# MCU_TIMER2_CFG register map
Vendor: Texas Instruments
Peripheral module from a debugger description file (folder J7_AHP).
Registers are 32-bit, read-write, reset 0x0 unless marked. A register's access mark holds for its fields unless they carry their own. Offsets are as the file gives them; lines under a group give offsets from that group; [hi:lo] are bit positions; {n}, {i} and the like mark numbered series; 'fields as' and 'values as' point back to an identical list; <NAME> marks a mode.

## MCU_TIMER2_CFG
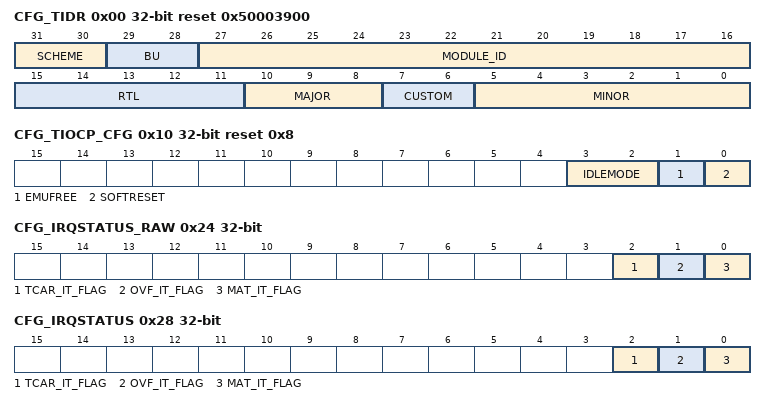
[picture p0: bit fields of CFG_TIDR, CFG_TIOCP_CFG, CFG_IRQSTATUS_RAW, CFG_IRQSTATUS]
0x00 CFG_TIDR ro reset 0x50003900
  [31:30] SCHEME — PID register scheme
  [29:28] BU — Business Unit
  [27:16] MODULE_ID
  [15:11] RTL — RTL revision. Will vary depending on release.
  [10:8] MAJOR — Major revision
  [7:6] CUSTOM
  [5:0] MINOR — Minor revision
0x10 CFG_TIOCP_CFG reset 0x8
  [3:2] IDLEMODE
  [1] EMUFREE — Emulation Mode
  [0] SOFTRESET — Software reset
0x20 CFG_IRQ_EOI
  [0] LINE_NUMBER — Idle Mode
0x24 CFG_IRQSTATUS_RAW access not given
  [2] TCAR_IT_FLAG — Capture Interrupt (access R/W1TS)
  [1] OVF_IT_FLAG — Overflow Interrupt (access R/W1TS)
  [0] MAT_IT_FLAG — Match Interrupt (access R/W1TS)
0x28 CFG_IRQSTATUS access not given
  [2] TCAR_IT_FLAG — Capture Interrupt (access R/W1TC)
  [1] OVF_IT_FLAG — Overflow Interrupt (access R/W1TC)
  [0] MAT_IT_FLAG — Match Interrupt (access R/W1TC)
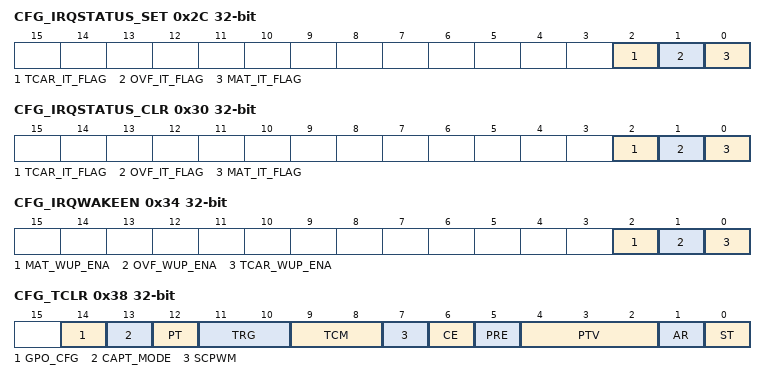
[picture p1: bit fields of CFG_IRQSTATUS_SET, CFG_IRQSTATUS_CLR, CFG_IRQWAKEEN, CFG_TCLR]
0x2C CFG_IRQSTATUS_SET access not given
  fields as CFG_IRQSTATUS_RAW
0x30 CFG_IRQSTATUS_CLR access not given
  fields as CFG_IRQSTATUS
0x34 CFG_IRQWAKEEN
  [2] MAT_WUP_ENA — Match Wakeup Enable
  [1] OVF_WUP_ENA — Overflow Wakeup Enable
  [0] TCAR_WUP_ENA — Capture Wakeup Enable
0x38 CFG_TCLR
  [14] GPO_CFG — This field drives directly the timer_gpocfg port
  [13] CAPT_MODE — Capture mode select bit; First/second
  [12] PT — Pulse or Toggle select bit
  [11:10] TRG — Trigger Output Mode
  [9:8] TCM — Transition Capture Mode
  [7] SCPWM — Pulse Width Modulation output pin default value
  [6] CE — Compare Enable
  [5] PRE — Prescaler Enable
  [4:2] PTV — Trigger Output Mode. The timer counter is prescaled with the value: 2^PTV
  [1] AR — Auto-reload mode
  [0] ST — Start/Stop timer control
0x3C CFG_TCRR
  [31:0] TIMER_COUNTER
0x40 CFG_TLDR
  [31:0] LOAD_VALUE — Timer Counter
0x44 CFG_TTGR
  [31:0] TTRG_VLAUE — The value of the trigger register. During reads, it always return 0xFFFF_FFFF
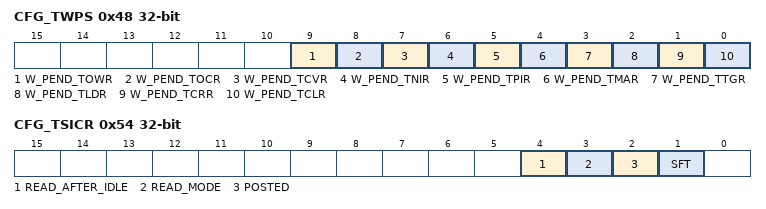
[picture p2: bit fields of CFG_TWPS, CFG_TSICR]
0x48 CFG_TWPS ro
  [9] W_PEND_TOWR — Write pending for register TOWR
  [8] W_PEND_TOCR — Write pending for register TOCR
  [7] W_PEND_TCVR — Write pending for register TCVR
  [6] W_PEND_TNIR — Write pending for register TNIR
  [5] W_PEND_TPIR — Write pending for register TPIR
  [4] W_PEND_TMAR — Write pending for register TMAR
  [3] W_PEND_TTGR — Write pending for register TTGR
  [2] W_PEND_TLDR — Write pending for register TLDR
  [1] W_PEND_TCRR — Write pending for register TCRR
  [0] W_PEND_TCLR — Write pending for register TCLR
0x4C CFG_TMAR
  [31:0] COMPARE_VLAUE — The value of the match register
0x50 CFG_TCAR1 ro
  [31:0] CAPTURE_VALUE1 — The value of first captured counter register
0x54 CFG_TSICR access per field
  [4] READ_AFTER_IDLE wo — Select if the synchronization mechanism used for first TCRR read operation after IDLE state is active
  [3] READ_MODE wo — Select posted/non-posted mode for read operation. This bit is not used when configured in posted mode
  [2] POSTED rw — Reset value of POSTED depends on hardware integration module at design time. Software must read POSTED field to get the hardwar module configuration
  [1] SFT rw — This bit reset all the functional part of teh module
0x58 CFG_TCAR2 ro
  [31:0] CAPTURE_VALUE2 — The value of second captured counter register
0x5C CFG_TPIR
  [31:0] POSITIVE_INC_VALUE — The value of the positive increment
0x60 CFG_TNIR
  [31:0] NEGATIVE_INC_VALUE — The value of the negative increment
0x64 CFG_TCVR
  [31:0] COUNTER_VALUE — The value of CVR counter
0x68 CFG_TOCR
  [23:0] OVF_COUNTER_VALUE — The number of overflow events
0x6C CFG_TOWR
  [23:0] OVF_WRAPPING_VALUE — The number of masked interrupts
